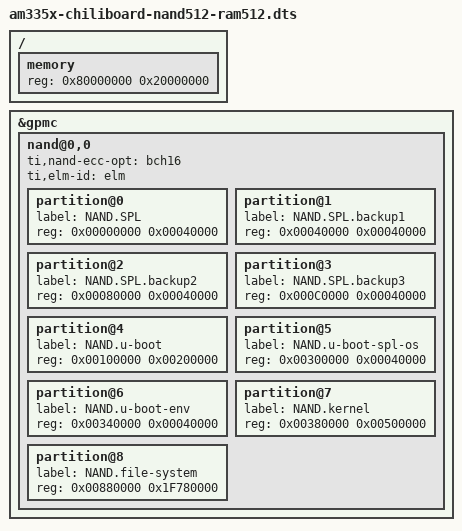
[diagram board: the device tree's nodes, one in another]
/*
 * Copyright (C) 2015 Grinn - http://www.grinn-global.com
 * Grzegorz Glomb <g.glomb@grinn-global.com>
 *
 * This program is free software; you can redistribute it and/or modify
 * it under the terms of the GNU General Public License version 2 as
 * published by the Free Software Foundation.
 */

/dts-v1/;

#include "am33xx.dtsi"
#include "am335x-chilisom-gcs2.dtsi"
#include "am335x-chiliboard-common.dtsi"
#include "am335x-chiliboard-all-gpio.dtsi"

/ {
	memory {
		reg = <0x80000000 0x20000000>; /* 512 MB */
	};
};

&gpmc {
	/* NAND 512MB */
	status = "okay";
	ranges = <0 0 0x08000000 0x20000000>;	/* CS0: NAND */
	nand@0,0 {
		ti,nand-ecc-opt= "bch16";
		ti,elm-id = <&elm>;
		#address-cells = <1>;
		#size-cells = <1>;
		partition@0 {
			label = "NAND.SPL";
			reg = <0x00000000 0x00040000>;
		};
		partition@1 {
			label = "NAND.SPL.backup1";
			reg = <0x00040000 0x00040000>;
		};
		partition@2 {
			label = "NAND.SPL.backup2";
			reg = <0x00080000 0x00040000>;
		};
		partition@3 {
			label = "NAND.SPL.backup3";
			reg = <0x000C0000 0x00040000>;
		};
		partition@4 {
			label = "NAND.u-boot";
			reg = <0x00100000 0x00200000>;
		};
		partition@5 {
			label = "NAND.u-boot-spl-os";
			reg = <0x00300000 0x00040000>;
		};
		partition@6 {
			label = "NAND.u-boot-env";
			reg = <0x00340000 0x00040000>;
		};
		partition@7 {
			label = "NAND.kernel";
			reg = <0x00380000 0x00500000>;
		};
		partition@8 {
			label = "NAND.file-system";
			reg = <0x00880000 0x1F780000>;
		};
	};
};
